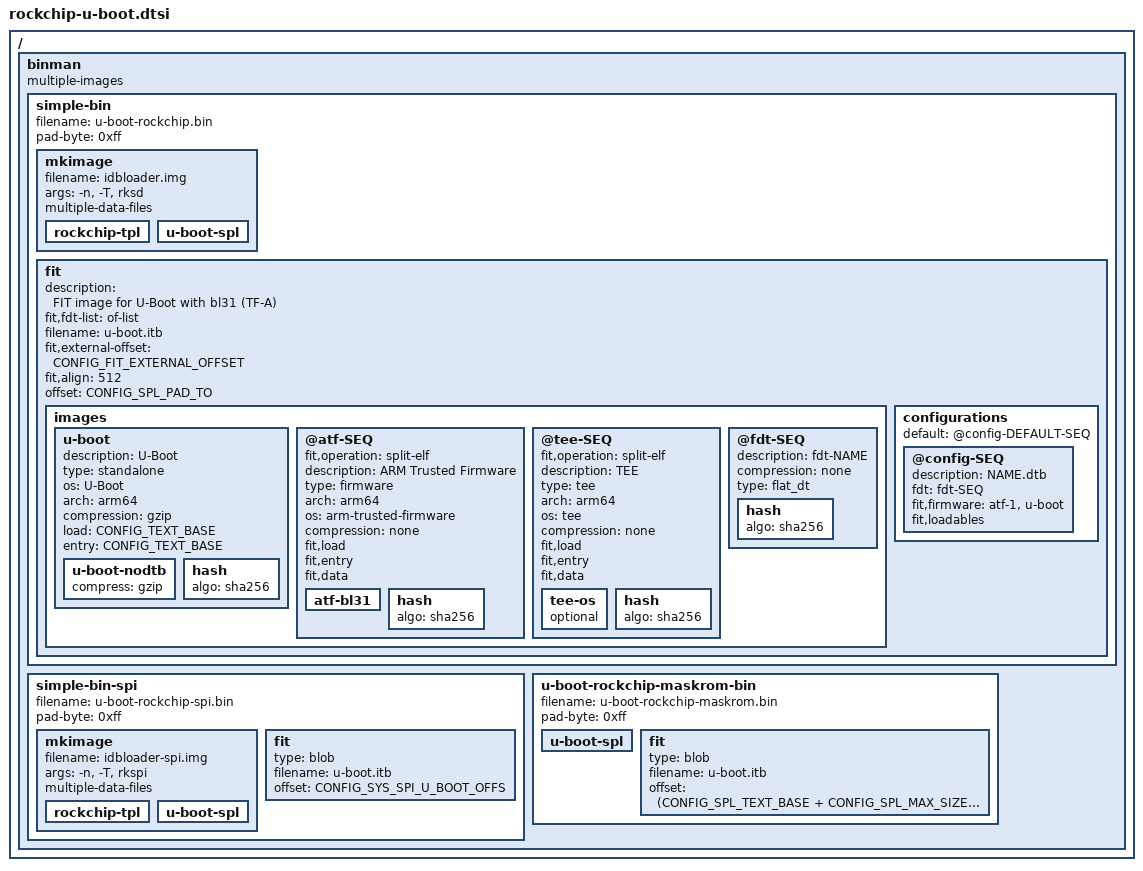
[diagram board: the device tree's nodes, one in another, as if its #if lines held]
// SPDX-License-Identifier: GPL-2.0+
/*
 * Copyright (C) 2019 Jagan Teki <jagan@amarulasolutions.com>
 */

#include <config.h>

/ {
	binman: binman {
		multiple-images;
	};
};

#ifdef CONFIG_SPL
&binman {
	/* Combination of TPL, SPL and U-Boot proper for use on eMMC, or SD cards. */
	simple-bin {
		filename = "u-boot-rockchip.bin";
		pad-byte = <0xff>;

		mkimage {
			filename = "idbloader.img";
			args = "-n", CONFIG_SYS_SOC, "-T", "rksd";
			multiple-data-files;

#ifdef CONFIG_ROCKCHIP_EXTERNAL_TPL
			rockchip-tpl {
			};
#elif defined(CONFIG_TPL)
			u-boot-tpl {
			};
#endif
			u-boot-spl {
			};
		};

#if defined(CONFIG_SPL_FIT) && (defined(CONFIG_ARM64) || defined(CONFIG_SPL_OPTEE_IMAGE))
		fit: fit {
#ifdef CONFIG_ARM64
			description = "FIT image for U-Boot with bl31 (TF-A)";
#else
			description = "FIT image with OP-TEE";
#endif
			#address-cells = <1>;
			fit,fdt-list = "of-list";
			filename = "u-boot.itb";
			fit,external-offset = <CONFIG_FIT_EXTERNAL_OFFSET>;
			fit,align = <512>;
			offset = <CONFIG_SPL_PAD_TO>;
			images {
				u-boot {
					description = "U-Boot";
					type = "standalone";
					os = "U-Boot";
#ifdef CONFIG_ARM64
					arch = "arm64";
#else
					arch = "arm";
#endif
#if defined(CONFIG_SPL_GZIP)
					compression = "gzip";
#elif defined(CONFIG_SPL_LZMA)
					compression = "lzma";
#else
					compression = "none";
#endif
					load = <CONFIG_TEXT_BASE>;
					entry = <CONFIG_TEXT_BASE>;
					u-boot-nodtb {
#if defined(CONFIG_SPL_GZIP)
					compress = "gzip";
#elif defined(CONFIG_SPL_LZMA)
					compress = "lzma";
#endif
					};
#ifdef CONFIG_SPL_FIT_SIGNATURE
					hash {
						algo = "sha256";
					};
#endif
				};

#ifdef CONFIG_ARM64
				@atf-SEQ {
					fit,operation = "split-elf";
					description = "ARM Trusted Firmware";
					type = "firmware";
					arch = "arm64";
					os = "arm-trusted-firmware";
					compression = "none";
					fit,load;
					fit,entry;
					fit,data;

					atf-bl31 {
					};
#ifdef CONFIG_SPL_FIT_SIGNATURE
					hash {
						algo = "sha256";
					};
#endif
				};
				@tee-SEQ {
					fit,operation = "split-elf";
					description = "TEE";
					type = "tee";
					arch = "arm64";
					os = "tee";
					compression = "none";
					fit,load;
					fit,entry;
					fit,data;

					tee-os {
						optional;
					};
#ifdef CONFIG_SPL_FIT_SIGNATURE
					hash {
						algo = "sha256";
					};
#endif
				};
#else
				op-tee {
					description = "OP-TEE";
					type = "tee";
					arch = "arm";
					os = "tee";
					compression = "none";
					load = <(CFG_SYS_SDRAM_BASE + 0x8400000)>;
					entry = <(CFG_SYS_SDRAM_BASE + 0x8400000)>;

					tee-os {
					};
#ifdef CONFIG_SPL_FIT_SIGNATURE
					hash {
						algo = "sha256";
					};
#endif
				};
#endif

				@fdt-SEQ {
					description = "fdt-NAME";
					compression = "none";
					type = "flat_dt";
#ifdef CONFIG_SPL_FIT_SIGNATURE
					hash {
						algo = "sha256";
					};
#endif
				};
			};

			configurations {
				default = "@config-DEFAULT-SEQ";
				@config-SEQ {
					description = "NAME.dtb";
					fdt = "fdt-SEQ";
#ifdef CONFIG_ARM64
					fit,firmware = "atf-1", "u-boot";
#else
					fit,firmware = "op-tee", "u-boot";
#endif
					fit,loadables;
				};
			};
		};
#else
		u-boot-img {
			offset = <CONFIG_SPL_PAD_TO>;
		};
#endif
	};

#ifdef CONFIG_ROCKCHIP_SPI_IMAGE
	simple-bin-spi {
		filename = "u-boot-rockchip-spi.bin";
		pad-byte = <0xff>;

		mkimage {
			filename = "idbloader-spi.img";
			args = "-n", CONFIG_SYS_SOC, "-T", "rkspi";
			multiple-data-files;

#ifdef CONFIG_ROCKCHIP_EXTERNAL_TPL
			rockchip-tpl {
			};
#elif defined(CONFIG_TPL)
			u-boot-tpl {
			};
#endif
			u-boot-spl {
			};
		};

#if defined(CONFIG_ARM64) || defined(CONFIG_SPL_OPTEE_IMAGE)
		fit {
			type = "blob";
			filename = "u-boot.itb";
#else
		u-boot-img {
#endif
			/* Sync with u-boot,spl-payload-offset if present */
			offset = <CONFIG_SYS_SPI_U_BOOT_OFFS>;
		};
	};
#endif /* CONFIG_ROCKCHIP_SPI_IMAGE */

#ifdef CONFIG_SPL_RAM_DEVICE
	/*
	 * Binary to be sent as 0x472 payload with `rockusb download-boot` or `rkdeveloptool db`.
	 * This cannot be ran when proper rockusb is running on the device (i.e. in most cases
	 * when a maskrom button is involved.)
	 */
	u-boot-rockchip-maskrom-bin {
		filename = "u-boot-rockchip-maskrom.bin";
		pad-byte = <0xff>;

		/* For now, the TPL is handled separately, as it needs to be sent prior to this binary. */
		/* Additionaly, `boot_merger` from Rockchip is assumed to be used to produce the final binary. */

		/* SPL output */
		u-boot-spl {
		};
		/* Reference to the actual U-Boot proper image, for spl-ram. */
#if defined(CONFIG_SPL_FIT) && (defined(CONFIG_ARM64) || defined(CONFIG_SPL_OPTEE_IMAGE))
		fit {
			type = "blob";
			filename = "u-boot.itb";
#else
		u-boot-img {
#endif
			/*
			 * The CONFIG_SPL_TEXT_BASE for SPL is 0x0.
			 * We can presume CONFIG_SPL_MAX_SIZE is safe to start from...
			 *
			 * On at least RK3588, atf-1 will be loaded at CONFIG_SPL_MAX_SIZE.
			 * Since this maskrom-bin is loaded at CONFIG_SPL_TEXT_BASE (0x0), will
			 * be clobbered when loading the contents of this FIT image.
			 * Thus, we're putting a *good enough* value this offset.
			 * Ideally, we would (aligned?) use SPL_TEXT_BASE + SPL_MAX_SIZE + BL31_MAX_SIZE.
			 * That is, if BL31 is always loaded at SPL_MAX_SIZE...
			 *
			 * The best outcome would be to have a way to make binman aware of overlaps
			 * between two unrelated images.
			 * For example, map `maskrom-bin` and the FIT image load *destinations* in
			 * the address space when building `maskrom-bin`, ensuring none of the parts
			 * from `maskrom-bin` overlap with the destinations from the FIT image.
			 */
			#define BL31_MAX_SIZE 0x40000
			offset = <(CONFIG_SPL_TEXT_BASE + CONFIG_SPL_MAX_SIZE + BL31_MAX_SIZE)>;
			/*
			 * Using CONFIG_SPL_PAD_TO works, but produces huge images. (9.2MB vs. 1.8MB)
			 */
			/* offset = <CONFIG_SPL_PAD_TO>; */
		};
	};
#endif /* CONFIG_SPL_RAM_DEVICE */
};
#endif /* CONFIG_SPL */
